# LM4F232H5QD register map
File version: 7944
ARM Cortex-M3 Stellaris Device
Registers are 32-bit, read-write, no defined reset value unless marked. A register's access mark holds for its fields unless they carry their own. Offsets are from the block's base; lines under a group give offsets from that group; [hi:lo] are bit positions; {n}, {i} and the like mark numbered series; 'fields as' and 'values as' point back to an identical list; <NAME> marks a mode.

## Memory map
0x40000000 WATCHDOG0 size 0x1000 — Register map for WATCHDOG0 peripheral
0x40001000 WATCHDOG1 size 0x1000
0x40004000 GPIO_PORTA size 0x1000 — Register map for GPIO_PORTA peripheral
0x40005000 GPIO_PORTB size 0x1000
0x40006000 GPIO_PORTC size 0x1000
0x40007000 GPIO_PORTD size 0x1000
0x40008000 SSI0 size 0x1000 — Register map for SSI0 peripheral
0x40009000 SSI1 size 0x1000
0x4000A000 SSI2 size 0x1000
0x4000B000 SSI3 size 0x1000
0x4000C000 UART0 size 0x1000 — Register map for UART0 peripheral
0x4000D000 UART1 size 0x1000
0x4000E000 UART2 size 0x1000
0x4000F000 UART3 size 0x1000
0x40010000 UART4 size 0x1000
0x40011000 UART5 size 0x1000
0x40012000 UART6 size 0x1000
0x40013000 UART7 size 0x1000
0x40020000 I2C0 size 0x1000 — Register map for I2C0 peripheral
0x40021000 I2C1 size 0x1000
0x40022000 I2C2 size 0x1000
0x40023000 I2C3 size 0x1000
0x40024000 GPIO_PORTE size 0x1000
0x40025000 GPIO_PORTF size 0x1000
0x40026000 GPIO_PORTG size 0x1000
0x40027000 GPIO_PORTH size 0x1000
0x40028000 PWM0 size 0x1000 — Register map for PWM0 peripheral
0x40029000 PWM1 size 0x1000
0x4002C000 QEI0 size 0x1000 — Register map for QEI0 peripheral
0x4002D000 QEI1 size 0x1000
0x40030000 TIMER0 size 0x1000 — Register map for TIMER0 peripheral
0x40031000 TIMER1 size 0x1000
0x40032000 TIMER2 size 0x1000
0x40033000 TIMER3 size 0x1000
0x40034000 TIMER4 size 0x1000
0x40035000 TIMER5 size 0x1000
0x40036000 WTIMER0 size 0x1000 — Register map for WTIMER0 peripheral
0x40037000 WTIMER1 size 0x1000
0x40038000 ADC0 size 0x1000 — Register map for ADC0 peripheral
0x40039000 ADC1 size 0x1000
0x4003C000 COMP size 0x1000 — Register map for COMP peripheral
0x4003D000 GPIO_PORTJ size 0x1000
0x40040000 CAN0 size 0x1000 — Register map for CAN0 peripheral
0x40041000 CAN1 size 0x1000
0x4004C000 WTIMER2 size 0x1000
0x4004D000 WTIMER3 size 0x1000
0x4004E000 WTIMER4 size 0x1000
0x4004F000 WTIMER5 size 0x1000
0x40050000 USB0 size 0x1000 — Register map for USB0 peripheral
0x40058000 GPIO_PORTA_AHB size 0x1000
0x40059000 GPIO_PORTB_AHB size 0x1000
0x4005A000 GPIO_PORTC_AHB size 0x1000
0x4005B000 GPIO_PORTD_AHB size 0x1000
0x4005C000 GPIO_PORTE_AHB size 0x1000
0x4005D000 GPIO_PORTF_AHB size 0x1000
0x4005E000 GPIO_PORTG_AHB size 0x1000
0x4005F000 GPIO_PORTH_AHB size 0x1000
0x40060000 GPIO_PORTJ_AHB size 0x1000
0x40061000 GPIO_PORTK size 0x1000
0x40062000 GPIO_PORTL size 0x1000
0x40063000 GPIO_PORTM size 0x1000
0x40064000 GPIO_PORTN size 0x1000
0x40065000 GPIO_PORTP size 0x1000
0x400AF000 EEPROM size 0x1000 — Register map for EEPROM peripheral
0x400C0000 I2C4 size 0x1000
0x400C1000 I2C5 size 0x1000
0x400F9000 SYSEXC size 0x1000 — Register map for SYSEXC peripheral
0x400FC000 HIB size 0x1000 — Register map for HIB peripheral
0x400FD000 FLASH_CTRL blocks up to offset 0x2000 — Register map for FLASH_CTRL peripheral
0x400FE000 SYSCTL size 0x1000 — Register map for SYSCTL peripheral
0x400FF000 UDMA size 0x1000 — Register map for UDMA peripheral
0xE000E000 NVIC size 0x1000 — Register map for NVIC peripheral

## Further device data
memory: FLASH description=FLASH Memory Map for lm4f232h5qd baseAddress=0x00000000
  offset=0 size=0x00040000 usage=FLASH Memory
memory: ROM description=ROM Memory Map for lm4f232h5qd baseAddress=0x01000000
  offset=0 size=0x00008c00 usage=ROM Boot Loader/StellarisWare
memory: SRAM description=SRAM Memory Map for lm4f232h5qd baseAddress=0x20000000
  offset=0 size=0x00008000 usage=SRAM

## WATCHDOG0 — Register map for WATCHDOG0 peripheral
Base 0x40000000; register names take the prefix WATCHDOG0
Same registers: WATCHDOG1 0x40001000 (register names take the prefix WATCHDOG1)
0x00 LOAD — Watchdog Load
  [31:0] WDT_LOAD — Watchdog Load Value
0x04 VALUE — Watchdog Value
  [31:0] WDT_VALUE
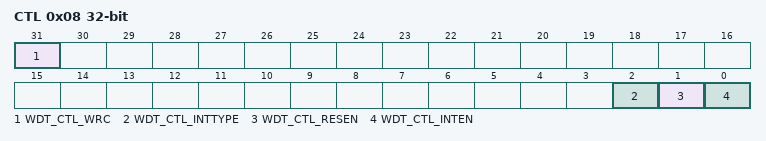
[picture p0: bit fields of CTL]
0x08 CTL — Watchdog Control
  [31] WDT_CTL_WRC — Write Complete
  [2] WDT_CTL_INTTYPE — Watchdog Interrupt Type
  [1] WDT_CTL_RESEN — Watchdog Reset Enable
  [0] WDT_CTL_INTEN — Watchdog Interrupt Enable
0x0C ICR wo — Watchdog Interrupt Clear
  [31:0] WDT_ICR
0x10 RIS — Watchdog Raw Interrupt Status
  [0] WDT_RIS_WDTRIS
0x14 MIS — Watchdog Masked Interrupt Status
  [0] WDT_MIS_WDTMIS
0x418 TEST — Watchdog Test
  [8] WDT_TEST_STALL — Watchdog Stall Enable
0xC00 LOCK — Watchdog Lock
  [31:0] WDT_LOCK
    0=WDT_LOCK_UNLOCKED (Unlocked); 1=WDT_LOCK_LOCKED (Locked)
